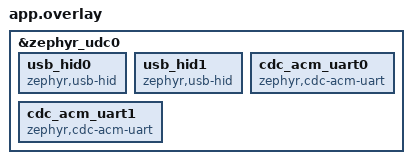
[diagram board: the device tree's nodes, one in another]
/*
 * Copyright (c) 2021 Nordic Semiconductor ASA
 *
 * SPDX-License-Identifier: Apache-2.0
 */

&zephyr_udc0 {
	usb_hid0: usb_hid0 {
		compatible = "zephyr,usb-hid";
	};

	usb_hid1: usb_hid1 {
		compatible = "zephyr,usb-hid";
	};

	cdc_acm_uart0 {
		compatible = "zephyr,cdc-acm-uart";
	};

	cdc_acm_uart1 {
		compatible = "zephyr,cdc-acm-uart";
	};
};
